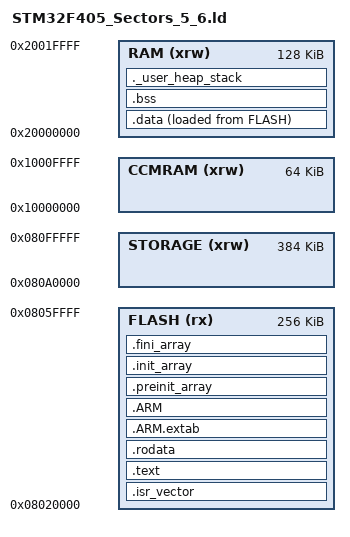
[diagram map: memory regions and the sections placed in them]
/* Generated by STM32 for VSCode for the 1 MB STM32F405.
 * Application image: Bank A (sectors 5 and 6) (256 KB)
 * STORAGE is sector 9 through sector 11; lower unused sectors are unassigned.
 * A bootloader must jump to this image and set VTOR to __flash_app_start__.
 */
ENTRY(Reset_Handler)

_estack = ORIGIN(RAM) + LENGTH(RAM);
_Min_Heap_Size = 0x200;
_Min_Stack_Size = 0x400;

MEMORY
{
  RAM (xrw)      : ORIGIN = 0x20000000, LENGTH = 128K
  CCMRAM (xrw)   : ORIGIN = 0x10000000, LENGTH = 64K
  FLASH (rx)     : ORIGIN = 0x08020000, LENGTH = 256K
  STORAGE (xrw)  : ORIGIN = 0x080A0000, LENGTH = 384K
}

/* Bounds for the application and storage partitions. */
__flash_storage_start__ = ORIGIN(STORAGE);
__flash_storage_end__ = ORIGIN(STORAGE) + LENGTH(STORAGE);
__flash_app_start__ = ORIGIN(FLASH);
__flash_app_end__ = ORIGIN(FLASH) + LENGTH(FLASH);

SECTIONS
{
  .isr_vector :
  {
    . = ALIGN(4);
    KEEP(*(.isr_vector))
    . = ALIGN(4);
  } >FLASH

  .text :
  {
    . = ALIGN(4);
    *(.text) *(.text*) *(.glue_7) *(.glue_7t) *(.eh_frame)
    KEEP(*(.init))
    KEEP(*(.fini))
    . = ALIGN(4);
    _etext = .;
  } >FLASH

  .rodata :
  {
    . = ALIGN(4);
    *(.rodata) *(.rodata*)
    . = ALIGN(4);
  } >FLASH

  .ARM.extab : { *(.ARM.extab* .gnu.linkonce.armextab.*) } >FLASH
  .ARM :
  {
    __exidx_start = .;
    *(.ARM.exidx*)
    __exidx_end = .;
  } >FLASH

  .preinit_array :
  {
    PROVIDE_HIDDEN(__preinit_array_start = .);
    KEEP(*(.preinit_array*))
    PROVIDE_HIDDEN(__preinit_array_end = .);
  } >FLASH
  .init_array :
  {
    PROVIDE_HIDDEN(__init_array_start = .);
    KEEP(*(SORT(.init_array.*)))
    KEEP(*(.init_array*))
    PROVIDE_HIDDEN(__init_array_end = .);
  } >FLASH
  .fini_array :
  {
    PROVIDE_HIDDEN(__fini_array_start = .);
    KEEP(*(SORT(.fini_array.*)))
    KEEP(*(.fini_array*))
    PROVIDE_HIDDEN(__fini_array_end = .);
  } >FLASH

  _sidata = LOADADDR(.data);
  .data :
  {
    . = ALIGN(4);
    _sdata = .;
    *(.data) *(.data*)
    . = ALIGN(4);
    _edata = .;
  } >RAM AT>FLASH

  .bss :
  {
    . = ALIGN(4);
    _sbss = .;
    __bss_start__ = _sbss;
    *(.bss) *(.bss*) *(COMMON)
    . = ALIGN(4);
    _ebss = .;
    __bss_end__ = _ebss;
  } >RAM

  ._user_heap_stack :
  {
    . = ALIGN(8);
    PROVIDE(end = .);
    PROVIDE(_end = .);
    . = . + _Min_Heap_Size;
    . = . + _Min_Stack_Size;
    . = ALIGN(8);
  } >RAM

  /DISCARD/ : { libc.a(*) libm.a(*) libgcc.a(*) }
  .ARM.attributes 0 : { *(.ARM.attributes) }
}
